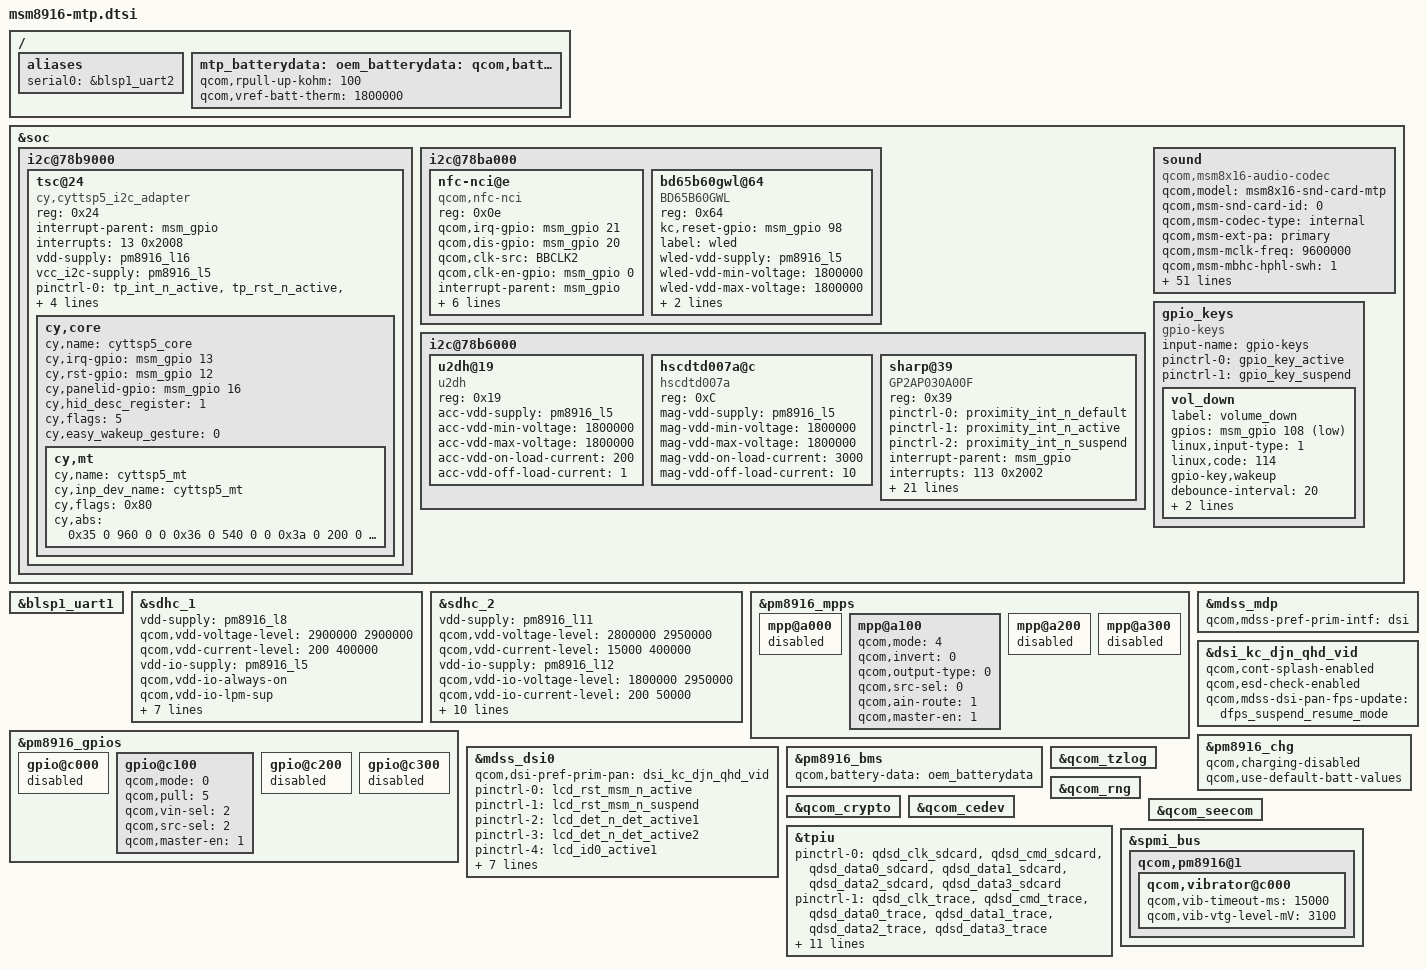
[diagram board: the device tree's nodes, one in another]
/* Copyright (c) 2014, The Linux Foundation. All rights reserved.
 *
 * This program is free software; you can redistribute it and/or modify
 * it under the terms of the GNU General Public License version 2 and
 * only version 2 as published by the Free Software Foundation.
 *
 * This program is distributed in the hope that it will be useful,
 * but WITHOUT ANY WARRANTY; without even the implied warranty of
 * MERCHANTABILITY or FITNESS FOR A PARTICULAR PURPOSE.  See the
 * GNU General Public License for more details.
 */
/*
 * This software is contributed or developed by KYOCERA Corporation.
 * (C) 2015 KYOCERA Corporation
 */

#include "msm8916.dtsi"
#include "msm8916-pinctrl.dtsi"
#include "msm8916-camera-sensor-mtp.dtsi"

/ {
	aliases {
		serial0 = &blsp1_uart2;
	};
};

&soc {
	i2c@78b9000 { /* BLSP1 QUP5 */
		tsc@24 {
			compatible = "cy,cyttsp5_i2c_adapter";
			reg = <0x24>;
			interrupt-parent = <&msm_gpio>;
			interrupts = <13 0x2008>;
			vdd-supply = <&pm8916_l16>;
			vcc_i2c-supply = <&pm8916_l5>;
			/* pins used by touchscreen */
			pinctrl-names = "pmx_ts_active","pmx_ts_suspend";
			pinctrl-0 = <&tp_int_n_active  &tp_rst_n_active &panel_id_active>;
			pinctrl-1 = <&tp_int_n_suspend &tp_rst_n_suspend &panel_id_suspend>;
			cy,adapter_id = "cyttsp5_i2c_adapter";
			cy,core {
				cy,name = "cyttsp5_core";
				cy,irq-gpio = <&msm_gpio 13 0x2008>;
				cy,rst-gpio = <&msm_gpio 12 0x0>;
				cy,panelid-gpio = <&msm_gpio 16 0x0>;
				cy,hid_desc_register = <1>;
				cy,flags = <5>;
				cy,easy_wakeup_gesture = <0>;
				cy,mt {
					cy,name = "cyttsp5_mt";
					cy,inp_dev_name = "cyttsp5_mt";
					cy,flags = <0x80>;
					cy,abs =
						<0x35 0 960 0 0
						0x36 0 540 0 0
						0x3a 0 200 0 0
						0xffff 0 255 0 0
						0x39 0 15 0 0
						0x30 0 20 0 0
						0x31 0 20 0 0
						0x34 0xffffff81 127 0 0
//						0x37 0 1 0 0
						/* ABS_DISTANCE, 0, 255, 0, 0 */
						0x19 0 255 0 0>;
//						cy,vkeys_x = <540>;
//						cy,vkeys_y = <960>;
				};
			};
		};
	};

	i2c@78ba000 { /* BLSP1 QUP6 */
		nfc-nci@e {
			compatible = "qcom,nfc-nci";
			reg = <0x0e>;
			qcom,irq-gpio = <&msm_gpio 21 0x00>;
			qcom,dis-gpio = <&msm_gpio 20 0x00>;
			qcom,clk-src = "BBCLK2";
			qcom,clk-en-gpio = <&msm_gpio 0 0x00>;
			interrupt-parent = <&msm_gpio>;
			interrupts = <21 0>;
			interrupt-names = "nfc_irq";
			pinctrl-names = "nfc_active","nfc_suspend";
			pinctrl-0 = <&nfc_int_active &nfc_disable_active>;
			pinctrl-1 = <&nfc_int_suspend &nfc_disable_suspend>;
			qcom,clk-gpio = <&pm8916_gpios 2 0>;
			clocks = <&clock_rpm clk_bb_clk2_pin>;
			clock-names = "ref_clk";
		};
		bd65b60gwl@64 {
			compatible = "BD65B60GWL";
			reg = <0x64>;
			kc,reset-gpio = <&msm_gpio 98 0x00>;
			label = "wled";
			wled-vdd-supply = <&pm8916_l5>;
			wled-vdd-min-voltage = <1800000>;
			wled-vdd-max-voltage = <1800000>;
			wled-vdd-on-load-current = <200>;
			wled-vdd-off-load-current = <10>;
		};
	};

	i2c@78b6000 { /* BLSP1 QUP2 */
//		mpu6050@68 { /* Gyroscope and accelerometer sensor combo */
//			compatible = "invn,mpu6050";
//			reg = <0x68>;
//			pinctrl-names = "mpu_default","mpu_sleep";
//			pinctrl-0 = <&mpu6050_default>;
//			pinctrl-1 = <&mpu6050_sleep>;
//			interrupt-parent = <&msm_gpio>;
//			interrupts = <115 0x2>;
//			vdd-supply = <&pm8916_l17>;
//			vlogic-supply = <&pm8916_l16>;
//			vi2c-supply = <&pm8916_l6>;
//			invn,gpio-int = <&msm_gpio 115 0x2>;
//			invn,place = "Portrait Down Back Side";
//		};

//		avago@39 { /* Ambient light and proximity sensor */
//			compatible = "avago,apds9900";
//			reg = <0x39>;
//			pinctrl-names = "default","sleep";
//			pinctrl-0 = <&apds99xx_default>;
//			pinctrl-1 = <&apds99xx_sleep>;
//			interrupt-parent = <&msm_gpio>;
//			interrupts = <113 0x2002>;
//			vdd-supply = <&pm8916_l17>;
//			vio-supply = <&pm8916_l6>;
//			avago,irq-gpio = <&msm_gpio 113 0x2002>;
//			avago,ps-threshold = <600>;
//			avago,ps-hysteresis-threshold = <500>;
//			avago,ps-pulse = <8>;
//			avago,ps-pgain = <0>;
//			avago,als-B = <223>;
//			avago,als-C = <70>;
//			avago,als-D = <142>;
//			avago,ga-value = <48>;
//		};

//		akm@c {
//			compatible = "ak,ak8963";
//			reg = <0x0c>;
//			pinctrl-names = "ak8963_default", "ak8963_sleep";
//			pinctrl-0 = <&ak8963_default>;
//			pinctrl-1 = <&ak8963_sleep>;
//			interrupt-parent = <&msm_gpio>;
//			interrupts = <69 0x2>;
//			vdd-supply = <&pm8916_l17>;
//			vio-supply = <&pm8916_l6>;
//			ak,layout = <0x6>;
//			ak,auto-report;
//		};
		u2dh@19 { /* Accelerometer sensor */
			compatible = "u2dh";
			reg = <0x19>;
			acc-vdd-supply = <&pm8916_l5>;
			acc-vdd-min-voltage = <1800000>;
			acc-vdd-max-voltage = <1800000>;
			acc-vdd-on-load-current = <200>;
			acc-vdd-off-load-current = <1>;
		};
		hscdtd007a@c { /* Geomagnetic sensor */
			compatible = "hscdtd007a";
			reg = <0xC>;
			mag-vdd-supply = <&pm8916_l5>;
			mag-vdd-min-voltage = <1800000>;
			mag-vdd-max-voltage = <1800000>;
			mag-vdd-on-load-current = <3000>;
			mag-vdd-off-load-current = <10>;
		};
		sharp@39 { /* Ambient light and proximity sensor */
			compatible = "GP2AP030A00F";
			reg = <0x39>;
			pinctrl-names = "default","active","suspend";
			pinctrl-0 = <&proximity_int_n_default>;
			pinctrl-1 = <&proximity_int_n_active>;
			pinctrl-2 = <&proximity_int_n_suspend>;
			interrupt-parent = <&msm_gpio>;
			interrupts = <113 0x2002>;
			sharp,irq-gpio = <&msm_gpio 113 0x2002>;
			light-vdd-supply = <&pm8916_l16>;
			light-vdd-min-voltage = <3000000>;
			light-vdd-max-voltage = <3000000>;
			light-vdd-on-load-current = <30000>;
			light-vdd-off-load-current = <100>;
			prox-vdd-supply = <&pm8916_l16>;
			prox-vdd-min-voltage = <3000000>;
			prox-vdd-max-voltage = <3000000>;
			prox-vdd-on-load-current = <30000>;
			prox-vdd-off-load-current = <100>;
			light-vdd-l5-supply = <&pm8916_l5>;
			light-vdd-l5-min-voltage = <1800000>;
			light-vdd-l5-max-voltage = <1800000>;
			light-vdd-l5-on-load-current = <3000>;
			light-vdd-l5-off-load-current = <10>;
			prox-vdd-l5-supply = <&pm8916_l5>;
			prox-vdd-l5-min-voltage = <1800000>;
			prox-vdd-l5-max-voltage = <1800000>;
			prox-vdd-l5-on-load-current = <3000>;
			prox-vdd-l5-off-load-current = <10>;
		};
	};

	sound {
		compatible = "qcom,msm8x16-audio-codec";
		qcom,model = "msm8x16-snd-card-mtp";
		qcom,msm-snd-card-id = <0>;
		qcom,msm-codec-type = "internal";
		qcom,msm-ext-pa = "primary";
		qcom,msm-mclk-freq = <9600000>;
//		qcom,msm-mbhc-hphl-swh = <0>;
		qcom,msm-mbhc-hphl-swh = <1>;
		qcom,msm-mbhc-gnd-swh = <0>;
//		qcom,msm-micbias1-ext-cap;
		qcom,msm-hs-micbias-type = "internal";
		qcom,audio-routing =
			"RX_BIAS", "MCLK",
			"SPK_RX_BIAS", "MCLK",
			"INT_LDO_H", "MCLK",
			"Ext Hac", "EAR",
/*
			"MIC BIAS External", "Handset Mic",
			"MIC BIAS Internal2", "Headset Mic",
			"MIC BIAS External", "Secondary Mic",
			"AMIC1", "MIC BIAS External",
			"AMIC2", "MIC BIAS Internal2",
			"AMIC3", "MIC BIAS External";
			"DMIC1", "MIC BIAS Internal1",
			"MIC BIAS Internal1", "Digital Mic1",
			"DMIC2", "MIC BIAS Internal1",
			"MIC BIAS Internal1", "Digital Mic2";
*/
			"MIC BIAS Internal1", "Handset Mic",
			"MIC BIAS Internal2", "Headset Mic",
			"MIC BIAS Internal3", "Secondary Mic",
			"AMIC1", "MIC BIAS Internal1",
			"AMIC2", "MIC BIAS Internal2",
			"AMIC3", "MIC BIAS Internal3";
		pinctrl-names = "cdc_lines_act",
				"cdc_lines_sus",
				"cdc_lines_sec_ext_act",
				"cdc_lines_sec_ext_sus",
				"cross_conn_det_act",
				"cross_conn_det_sus";
		pinctrl-0 = <&cdc_pdm_lines_act>;
		pinctrl-1 = <&cdc_pdm_lines_sus>;
		pinctrl-2 = <&cdc_pdm_lines_act &cdc_ext_pa_act
						&cdc_ext_pa_ws_act>;
		pinctrl-3 = <&cdc_pdm_lines_sus &cdc_ext_pa_sus
						&cdc_ext_pa_ws_sus>;
		pinctrl-4 = <&cross_conn_det_act>;
		pinctrl-5 = <&cross_conn_det_sus>;
//		qcom,cdc-us-euro-gpios = <&msm_gpio 120 0>;
		asoc-platform = <&pcm0>, <&pcm1>, <&voip>, <&voice>,
				<&loopback>, <&compress>, <&hostless>,
				<&afe>, <&lsm>, <&routing>, <&lpa>;
		asoc-platform-names = "msm-pcm-dsp.0", "msm-pcm-dsp.1",
				"msm-voip-dsp", "msm-pcm-voice", "msm-pcm-loopback",
				"msm-compress-dsp", "msm-pcm-hostless", "msm-pcm-afe",
				"msm-lsm-client", "msm-pcm-routing", "msm-pcm-lpa";
		asoc-cpu = <&dai_pri_auxpcm>, <&dai_hdmi>,
				<&dai_mi2s0>, <&dai_mi2s1>, <&dai_mi2s2>, <&dai_mi2s3>,
				<&sb_0_rx>, <&sb_0_tx>, <&sb_1_rx>, <&sb_1_tx>,
				<&sb_3_rx>, <&sb_3_tx>, <&sb_4_rx>, <&sb_4_tx>,
				<&bt_sco_rx>, <&bt_sco_tx>, <&int_fm_rx>, <&int_fm_tx>,
				<&afe_pcm_rx>, <&afe_pcm_tx>, <&afe_proxy_rx>, <&afe_proxy_tx>,
				<&incall_record_rx>, <&incall_record_tx>, <&incall_music_rx>,
				<&incall_music_2_rx>;
		asoc-cpu-names = "msm-dai-q6-auxpcm.1", "msm-dai-q6-hdmi.8",
				"msm-dai-q6-mi2s.0", "msm-dai-q6-mi2s.1",
				"msm-dai-q6-mi2s.2", "msm-dai-q6-mi2s.3",
				"msm-dai-q6-dev.16384", "msm-dai-q6-dev.16385",
				"msm-dai-q6-dev.16386", "msm-dai-q6-dev.16387",
				"msm-dai-q6-dev.16390", "msm-dai-q6-dev.16391",
				"msm-dai-q6-dev.16392", "msm-dai-q6-dev.16393",
				"msm-dai-q6-dev.12288", "msm-dai-q6-dev.12289",
				"msm-dai-q6-dev.12292", "msm-dai-q6-dev.12293",
				"msm-dai-q6-dev.224", "msm-dai-q6-dev.225",
				"msm-dai-q6-dev.241", "msm-dai-q6-dev.240",
				"msm-dai-q6-dev.32771", "msm-dai-q6-dev.32772",
				"msm-dai-q6-dev.32773", "msm-dai-q6-dev.32770";
		asoc-codec = <&stub_codec>, <&pm8916_tombak_dig>;
		asoc-codec-names = "msm-stub-codec.1", "tombak_codec";
	};
};

/*
&blsp1_uart2 {
	status = "ok";
	pinctrl-names = "default";
	pinctrl-0 = <&uart_console_sleep>;
};
*/

&soc {
	gpio_keys {
		compatible = "gpio-keys";
		input-name = "gpio-keys";
		pinctrl-names = "tlmm_gpio_key_active","tlmm_gpio_key_suspend";
		pinctrl-0 = <&gpio_key_active>;
		pinctrl-1 = <&gpio_key_suspend>;

		vol_down {
			label = "volume_down";
			gpios = <&msm_gpio 108 0x1>;
			linux,input-type = <1>;
			linux,code = <114>;
			gpio-key,wakeup;
			debounce-interval = <20>;
			on_chattering_num  = <1>;
			off_chattering_num = <0>;
		};
	};
};

&blsp1_uart1 {
	status = "ok";
};

&sdhc_1 {
	vdd-supply = <&pm8916_l8>;
	qcom,vdd-voltage-level = <2900000 2900000>;
	qcom,vdd-current-level = <200 400000>;

	vdd-io-supply = <&pm8916_l5>;
	qcom,vdd-io-always-on;
	qcom,vdd-io-lpm-sup;
	qcom,vdd-io-voltage-level = <1800000 1800000>;
	qcom,vdd-io-current-level = <200 60000>;

	pinctrl-names = "active", "sleep";
	pinctrl-0 = <&sdc1_clk_on &sdc1_cmd_on &sdc1_data_on>;
	pinctrl-1 = <&sdc1_clk_off &sdc1_cmd_off &sdc1_data_off>;

	qcom,nonremovable;

	status = "ok";
};

&sdhc_2 {
	vdd-supply = <&pm8916_l11>;
	qcom,vdd-voltage-level = <2800000 2950000>;
	qcom,vdd-current-level = <15000 400000>;

	vdd-io-supply = <&pm8916_l12>;
	qcom,vdd-io-voltage-level = <1800000 2950000>;
	qcom,vdd-io-current-level = <200 50000>;

	pinctrl-names = "active", "sleep";
	pinctrl-0 = <&sdc2_clk_on &sdc2_cmd_on &sdc2_data_on &sdc2_cd_on>;
	pinctrl-1 = <&sdc2_clk_off &sdc2_cmd_off &sdc2_data_off &sdc2_cd_off>;

	#address-cells = <0>;
	interrupt-parent = <&sdhc_2>;
	interrupts = <0 1 2>;
	#interrupt-cells = <1>;
	interrupt-map-mask = <0xffffffff>;
	interrupt-map = <0 &intc 0 125 0
			1 &intc 0 221 0
			2 &msm_gpio 38 0>;
	interrupt-names = "hc_irq", "pwr_irq", "status_irq";
	cd-gpios = <&msm_gpio 38 0x1>;

	status = "ok";
};

&pm8916_mpps {
	mpp@a000 { /* MPP 1 */
		/* VDD_PX */
		status = "disabled";
	};

	mpp@a100 { /* MPP 2 */
		/* VCHG */
		status = "ok"; 
		qcom,mode = <4>;			/* Analog Input */
		qcom,invert = <0>;			/* No Invert */
		qcom,output-type = <0>;		/* CMOS */
		qcom,src-sel = <0>;			/* QPNP_PIN_SEL_FUNC_CONSTANT */
		qcom,ain-route = <1>;		/* QPNP_PIN_AIN_AMUX_CH8 */
		qcom,master-en = <1>;		/* Enable MPP */
	};

	mpp@a200 { /* MPP 3 */
		/* VREF DAC */
		status = "disabled";
	};

	mpp@a300 { /* MPP 4 */
		/* N/C */
		status = "disabled";
	};
};

&pm8916_gpios {
	gpio@c000 { /* GPIO 1 */
		/* Battery UICC Alarm */
		status = "disabled";
	};

	gpio@c100 { /* GPIO 2 */
		/* NFC_CLK_REQ */
		qcom,mode = <0>; /* QPNP_PIN_MODE_DIG_IN */
		qcom,pull = <5>; /* QPNP_PIN_PULL_NO */
		qcom,vin-sel = <2>; /* QPNP_PIN_VIN2 */
		qcom,src-sel = <2>; /* QPNP_PIN_SEL_FUNC_1 */
		qcom,master-en = <1>;
	};

	gpio@c200 { /* GPIO 3 */
		/* External regulator control for WTR */
		status = "disabled";
	};

	gpio@c300 { /* GPIO 4 */
		/* External regulator control for APC */
		status = "disabled";
	};
};

#include "dsi-panel-kc-djn-qhd-video.dtsi"

&mdss_mdp {
	qcom,mdss-pref-prim-intf = "dsi";
};

&mdss_dsi0 {
	qcom,dsi-pref-prim-pan = <&dsi_kc_djn_qhd_vid>;
	pinctrl-names = "mdss_default", "mdss_sleep", "mdss_det_active1", "mdss_det_active2",
			"lcd_id0_active1", "lcd_id0_active2", "lcd_id1_active1", "lcd_id1_active2";
	pinctrl-0 = <&lcd_rst_msm_n_active>;
	pinctrl-1 = <&lcd_rst_msm_n_suspend>;
	pinctrl-2 = <&lcd_det_n_det_active1>;
	pinctrl-3 = <&lcd_det_n_det_active2>;
	pinctrl-4 = <&lcd_id0_active1>;
	pinctrl-5 = <&lcd_id0_active2>;
	pinctrl-6 = <&lcd_id1_active1>;
	pinctrl-7 = <&lcd_id1_active2>;

	qcom,platform-reset-gpio = <&msm_gpio 25 0>;
	qcom,platform-lcd_det-gpio = <&msm_gpio 31 0>;
	qcom,platform-lcd_id0-gpio = <&msm_gpio 33 0>;
	qcom,platform-lcd_id1-gpio = <&msm_gpio 69 0>;
};

&dsi_kc_djn_qhd_vid {
	qcom,cont-splash-enabled;
	qcom,esd-check-enabled;
//	qcom,mdss-dsi-pan-enable-dynamic-fps;
	qcom,mdss-dsi-pan-fps-update = "dfps_suspend_resume_mode";
};

&pm8916_chg {
	status = "ok";
	qcom,charging-disabled;
	qcom,use-default-batt-values;
};

/ {
	mtp_batterydata: qcom,battery-data {
		qcom,rpull-up-kohm = <100>;
		qcom,vref-batt-therm = <1800000>;

		#include "batterydata-palladium.dtsi"
	};
};

/ {
	oem_batterydata: qcom,battery-data {
		qcom,rpull-up-kohm = <100>;
		qcom,vref-batt-therm = <1800000>;

		#include "batterydata-oem.dtsi"
	};
};

&pm8916_bms {
	status = "ok";
	//qcom,battery-data = <&mtp_batterydata>;
	qcom,battery-data = <&oem_batterydata>;
};

&qcom_tzlog {
	status = "okay";
};

&qcom_rng {
	status = "okay";
};

&qcom_crypto {
	status = "okay";
};

&qcom_cedev {
	status = "okay";
};

&qcom_seecom {
	status = "okay";
};

/* CoreSight */
&tpiu {
      pinctrl-names = "sdcard", "trace", "swduart",
		      "swdtrc", "jtag", "spmi";
       /* NIDnT */
      pinctrl-0 = <&qdsd_clk_sdcard &qdsd_cmd_sdcard
                  &qdsd_data0_sdcard &qdsd_data1_sdcard
                  &qdsd_data2_sdcard &qdsd_data3_sdcard>;
      pinctrl-1 = <&qdsd_clk_trace &qdsd_cmd_trace
                  &qdsd_data0_trace &qdsd_data1_trace
                  &qdsd_data2_trace &qdsd_data3_trace>;
      pinctrl-2 = <&qdsd_cmd_swduart &qdsd_data0_swduart
                  &qdsd_data1_swduart &qdsd_data2_swduart
                  &qdsd_data3_swduart>;
      pinctrl-3 = <&qdsd_clk_swdtrc &qdsd_cmd_swdtrc
                  &qdsd_data0_swdtrc &qdsd_data1_swdtrc
                  &qdsd_data2_swdtrc &qdsd_data3_swdtrc>;
      pinctrl-4 = <&qdsd_cmd_jtag &qdsd_data0_jtag
                  &qdsd_data1_jtag &qdsd_data2_jtag
                  &qdsd_data3_jtag>;
      pinctrl-5 = <&qdsd_clk_spmi &qdsd_cmd_spmi
                  &qdsd_data0_spmi &qdsd_data3_spmi>;
};

&spmi_bus {
	qcom,pm8916@1 {
		qcom,vibrator@c000 {
			status = "okay";
			qcom,vib-timeout-ms = <15000>;
			qcom,vib-vtg-level-mV = <3100>;
		};
	};
};
